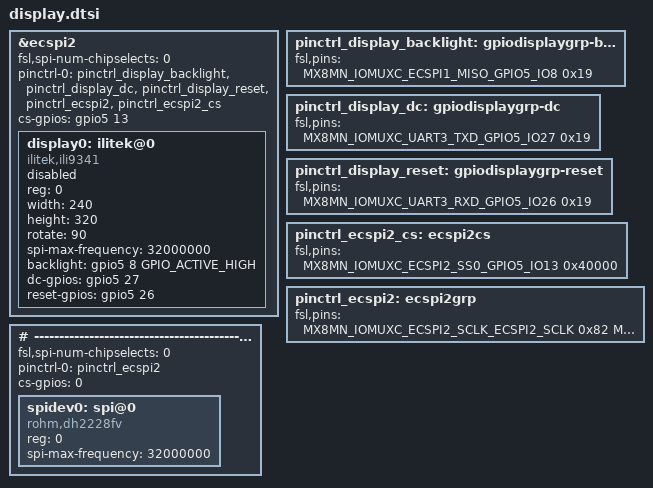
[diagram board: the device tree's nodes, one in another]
&ecspi2 {
	#address-cells = <1>;
	#size-cells = <0>;
	fsl,spi-num-chipselects = <0>;
	pinctrl-names = "default";
	pinctrl-0 = <&pinctrl_display_backlight &pinctrl_display_dc &pinctrl_display_reset &pinctrl_ecspi2 &pinctrl_ecspi2_cs>;
	cs-gpios = <&gpio5 13 GPIO_ACTIVE_HIGH>;
	status = "okay";

	display0: ilitek@0{
		compatible = "ilitek,ili9341";
		reg = <0>;
		width = <240>;
		height = <320>;
		rotate = <90>;
		spi-max-frequency = <32000000>;
		backlight = <&gpio5 8 GPIO_ACTIVE_HIGH>;
		dc-gpios = <&gpio5 27 GPIO_ACTIVE_HIGH>;
		reset-gpios = <&gpio5 26 GPIO_ACTIVE_HIGH>;
		status =  "okay ";
	};
};

pinctrl_display_backlight: gpiodisplaygrp-backlight {
	fsl,pins = <
		MX8MN_IOMUXC_ECSPI1_MISO_GPIO5_IO8		0x19
	>;
};

pinctrl_display_dc: gpiodisplaygrp-dc {
	fsl,pins = <
		MX8MN_IOMUXC_UART3_TXD_GPIO5_IO27		0x19
	>;
};

pinctrl_display_reset: gpiodisplaygrp-reset {
	fsl,pins = <
		MX8MN_IOMUXC_UART3_RXD_GPIO5_IO26		0x19
	>;
};

pinctrl_ecspi2_cs: ecspi2cs {
	fsl,pins = <
		MX8MN_IOMUXC_ECSPI2_SS0_GPIO5_IO13		0x40000
	>;
};

pinctrl_ecspi2: ecspi2grp {
	fsl,pins = <
		MX8MN_IOMUXC_ECSPI2_SCLK_ECSPI2_SCLK		0x82
		MX8MN_IOMUXC_ECSPI2_MOSI_ECSPI2_MOSI		0x82
		MX8MN_IOMUXC_ECSPI2_MISO_ECSPI2_MISO		0x82
	>;
};

# -------------------------------------------------------------------

&ecspi2 {
	#address-cells = <1>;
	#size-cells = <0>;
	pinctrl-names = "default";
	fsl,spi-num-chipselects = <0>;
	// fsl,spi-num-chipselects = <1>;
	pinctrl-0 = <&pinctrl_ecspi2>;
	// pinctrl-0 = <&pinctrl_ecspi2 &pinctrl_ecspi2_cs>;
	cs-gpios = <0>;
	// cs-gpios = <&gpio5 13 GPIO_ACTIVE_LOW>;
	status = "okay";

	spidev0: spi@0{
		reg = <0>;
		compatible = "rohm,dh2228fv";
		spi-max-frequency = <32000000>;
	};
};

// pinctrl_ecspi2_cs: ecspi2cs {
// 	fsl,pins = <
// 		MX8MN_IOMUXC_ECSPI2_SS0_GPIO5_IO13		0x40000
// 	>;
// };

pinctrl_ecspi2: ecspi2grp {
	fsl,pins = <
		MX8MN_IOMUXC_ECSPI2_SCLK_ECSPI2_SCLK		0x82
		MX8MN_IOMUXC_ECSPI2_MOSI_ECSPI2_MOSI		0x82
		MX8MN_IOMUXC_ECSPI2_MISO_ECSPI2_MISO		0x82
	>;
};
